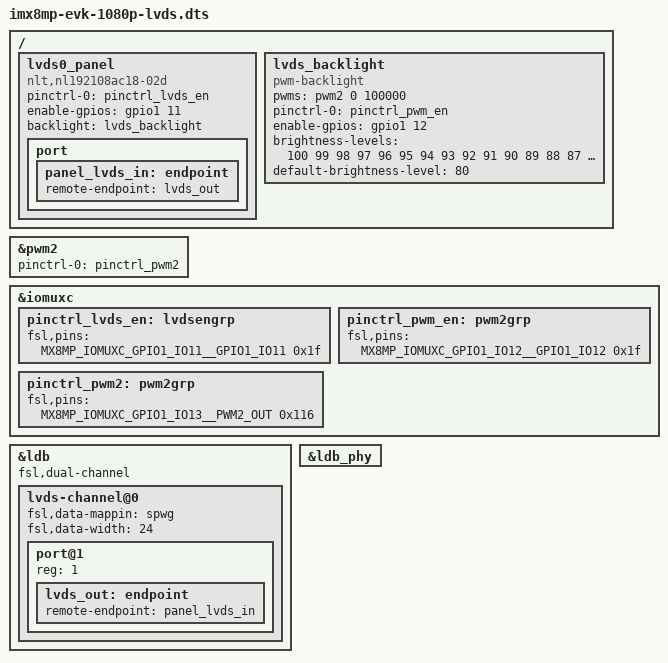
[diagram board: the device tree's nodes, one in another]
// SPDX-License-Identifier: GPL-2.0+
/*
 * Copyright 2020 NXP
 */

#include "imx8mp-evk.dts"

/ {
	lvds0_panel {
		//compatible = "debix,HC050IG40029-D58V.C";
		compatible = "nlt,nl192108ac18-02d";
		pinctrl-names = "default";
		pinctrl-0 = <&pinctrl_lvds_en>;
		enable-gpios = <&gpio1 11 GPIO_ACTIVE_HIGH>;
		
		backlight = <&lvds_backlight>;

		port {
			panel_lvds_in: endpoint {
				remote-endpoint = <&lvds_out>;
			};
		};
	};
        lvds_backlight: lvds_backlight {
                compatible = "pwm-backlight";
                pwms = <&pwm2 0 100000>;
                status = "okay";
                pinctrl-0 = <&pinctrl_pwm_en>;
                enable-gpios = <&gpio1 12 GPIO_ACTIVE_HIGH>;
#if 0
                brightness-levels = < 0  1  2  3  4  5  6  7  8  9
                                     10 11 12 13 14 15 16 17 18 19
                                     20 21 22 23 24 25 26 27 28 29
                                     30 31 32 33 34 35 36 37 38 39
                                     40 41 42 43 44 45 46 47 48 49
                                     50 51 52 53 54 55 56 57 58 59
                                     60 61 62 63 64 65 66 67 68 69
                                     70 71 72 73 74 75 76 77 78 79
                                     80 81 82 83 84 85 86 87 88 89
                                     90 91 92 93 94 95 96 97 98 99
                                    100>;
#else
		brightness-levels = <100 99 98 97 96 95 94 93 92 91 
                                     90 89 88 87 86 85 84 83 82 81 
                                     80 79 78 77 76 75 74 73 72 71 
                                     70 69 68 67 66 65 64 63 62 61 
                                     60 59 58 57 56 55 54 53 52 51 
                                     50 49 48 47 46 45 44 43 42 41 
				     40 39 38 37 36 35 34 33 32 31 
                                     30 29 28 27 26 25 24 23 22 21 
				     20 19 18 17 16 15 14 13 12 11 
                                     10 9 8 7 6 5 4 3 2 1 0>;
#endif

                default-brightness-level = <80>;
        };

};



&pwm2 {
        pinctrl-names = "default";
        pinctrl-0 = <&pinctrl_pwm2>;
        status = "okay";
}; 

&iomuxc {
        pinctrl_lvds_en: lvdsengrp {
 		fsl,pins = <
                        MX8MP_IOMUXC_GPIO1_IO11__GPIO1_IO11     0x1f
                >;
        };

	pinctrl_pwm_en: pwm2grp {
                fsl,pins = <
                        MX8MP_IOMUXC_GPIO1_IO12__GPIO1_IO12 0x1f
                >;
        };

        pinctrl_pwm2: pwm2grp {
                fsl,pins = <
			MX8MP_IOMUXC_GPIO1_IO13__PWM2_OUT	0x116
                >;
        };
};


///delete-node/ &lvds_bridge;

&ldb {
	status = "okay";
	fsl,dual-channel;

	lvds-channel@0 {
		//fsl,data-mapping = "jeida";
		fsl,data-mappin  = "spwg";
		fsl,data-width = <24>;
		status = "okay";

		/delete-node/ port@1;

		port@1 {
			reg = <1>;

			lvds_out: endpoint {
				remote-endpoint = <&panel_lvds_in>;
			};
		};
	};
};

&ldb_phy {
	status = "okay"; 
};
